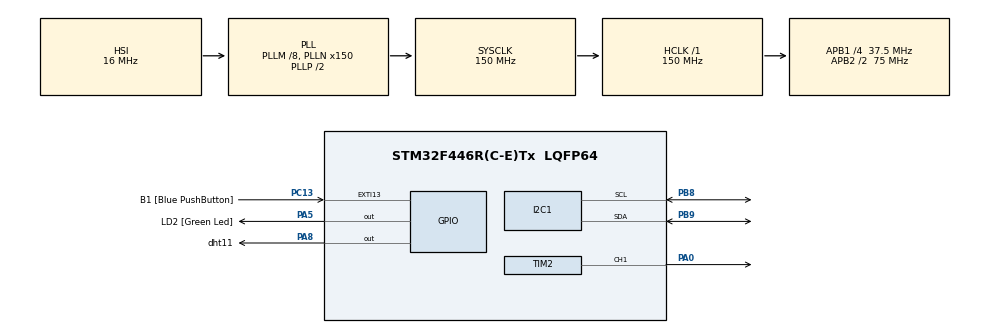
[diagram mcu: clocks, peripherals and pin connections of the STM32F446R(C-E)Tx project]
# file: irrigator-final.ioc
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I2C1.I2C_Mode=I2C_Fast
Mcu.Family=STM32F4
Mcu.Name=STM32F446R(C-E)Tx
Mcu.Package=LQFP64
NVIC.PriorityGroup=NVIC_PRIORITYGROUP_0
PA0-WKUP.Signal=S_TIM2_CH1_ETR
PA5.GPIO_Label=LD2 [Green Led]
PA5.Signal=GPIO_Output
PA8.GPIO_Label=dht11
PA8.GPIO_Speed=GPIO_SPEED_FREQ_VERY_HIGH
PA8.PinState=GPIO_PIN_SET
PA8.Signal=GPIO_Output
PB8.Mode=I2C
PB8.Signal=I2C1_SCL
PB9.Mode=I2C
PB9.Signal=I2C1_SDA
PC13.GPIO_Label=B1 [Blue PushButton]
PC13.GPIO_ModeDefaultEXTI=GPIO_MODE_IT_FALLING
PC13.Signal=GPXTI13
PC14-OSC32_IN.Mode=LSE-External-Oscillator
PC14-OSC32_IN.Signal=RCC_OSC32_IN
PC15-OSC32_OUT.Mode=LSE-External-Oscillator
PC15-OSC32_OUT.Signal=RCC_OSC32_OUT
PH0-OSC_IN.Mode=HSE-External-Oscillator
PH0-OSC_IN.Signal=RCC_OSC_IN
PH1-OSC_OUT.Mode=HSE-External-Oscillator
PH1-OSC_OUT.Signal=RCC_OSC_OUT
ProjectManager.HeapSize=0x200
ProjectManager.StackSize=0x400
ProjectManager.TargetToolchain=STM32CubeIDE
RCC.AHBFreq_Value=150000000
RCC.APB1CLKDivider=RCC_HCLK_DIV4
RCC.APB1Freq_Value=37500000
RCC.APB1TimFreq_Value=75000000
RCC.APB2CLKDivider=RCC_HCLK_DIV2
RCC.APB2Freq_Value=75000000
RCC.APB2TimFreq_Value=150000000
RCC.CortexFreq_Value=150000000
RCC.FLatency-AdvancedSettings=FLASH_LATENCY_4
RCC.HCLKFreq_Value=150000000
RCC.HSE_VALUE=8000000
RCC.HSI_VALUE=16000000
RCC.PLLM=8
RCC.PLLN=150
RCC.SYSCLKFreq_VALUE=150000000
RCC.SYSCLKSource=RCC_SYSCLKSOURCE_PLLCLK
RCC.USBFreq_Value=150000000
RCC.VCOOutputFreq_Value=300000000
SH.S_TIM2_CH1_ETR.0=TIM2_CH1,PWM Generation1 CH1
TIM2.Channel-PWM\ Generation1\ CH1=TIM_CHANNEL_1
TIM2.Period=1000-1
TIM2.Prescaler=1680-1
VP_TIM2_VS_ClockSourceINT.Mode=Internal
board=NUCLEO-F446RE

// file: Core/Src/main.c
/* USER CODE BEGIN Header */
/**
  ******************************************************************************
  * @file           : main.c
  * @brief          : Main program body
  ******************************************************************************
  * @attention
  *
  * Copyright (c) 2024 STMicroelectronics.
  * All rights reserved.
  *
  * This software is licensed under terms that can be found in the LICENSE file
  * in the root directory of this software component.
  * If no LICENSE file comes with this software, it is provided AS-IS.
  *
  ******************************************************************************
  */
/* USER CODE END Header */
#include "main.h"

/* USER CODE BEGIN Includes */
#include <stdio.h>
#include "ssd1306.h"
#include "timer_display.h"
#include "servo_control.h"
#include "pir_control.h"

/* USER CODE END Includes */

I2C_HandleTypeDef hi2c1;

TIM_HandleTypeDef htim2;

/* USER CODE BEGIN PV */

/* USER CODE BEGIN PV */
/* USER CODE END PV */

void SystemClock_Config(void);
static void MX_GPIO_Init(void);
static void MX_I2C1_Init(void);
static void MX_TIM2_Init(void);

int main(void)
{

  /* MCU Configuration--------------------------------------------------------*/

  /* Reset of all peripherals, Initializes the Flash interface and the Systick. */
  HAL_Init();

  /* Configure the system clock */
  SystemClock_Config();

  /* Initialize all configured peripherals */
  MX_GPIO_Init();
  MX_I2C1_Init();
  MX_TIM2_Init();
  /* USER CODE BEGIN 2 */
  /* USER CODE BEGIN 2 */

  Timer_Display_Init();
	Servo_Init();

  /* USER CODE END 2 */

  /* Infinite loop */
  /* USER CODE BEGIN WHILE */
  while (1)
  {
  	Timer_Display_Update();
		PIR_Process();
    /* USER CODE END WHILE */

  }
}

void SystemClock_Config(void)
{
  RCC_OscInitTypeDef RCC_OscInitStruct = {0};
  RCC_ClkInitTypeDef RCC_ClkInitStruct = {0};

  /** Configure the main internal regulator output voltage
  */
  __HAL_RCC_PWR_CLK_ENABLE();
  __HAL_PWR_VOLTAGESCALING_CONFIG(PWR_REGULATOR_VOLTAGE_SCALE1);

  /** Initializes the RCC Oscillators according to the specified parameters
  * in the RCC_OscInitTypeDef structure.
  */
  RCC_OscInitStruct.OscillatorType = RCC_OSCILLATORTYPE_HSI;
  RCC_OscInitStruct.HSIState = RCC_HSI_ON;
  RCC_OscInitStruct.HSICalibrationValue = RCC_HSICALIBRATION_DEFAULT;
  RCC_OscInitStruct.PLL.PLLState = RCC_PLL_ON;
  RCC_OscInitStruct.PLL.PLLSource = RCC_PLLSOURCE_HSI;
  RCC_OscInitStruct.PLL.PLLM = 8;
  RCC_OscInitStruct.PLL.PLLN = 150;
  RCC_OscInitStruct.PLL.PLLP = RCC_PLLP_DIV2;
  RCC_OscInitStruct.PLL.PLLQ = 2;
  RCC_OscInitStruct.PLL.PLLR = 2;
  if (HAL_RCC_OscConfig(&RCC_OscInitStruct) != HAL_OK)
  {
    Error_Handler();
  }

  /** Initializes the CPU, AHB and APB buses clocks
  */
  RCC_ClkInitStruct.ClockType = RCC_CLOCKTYPE_HCLK|RCC_CLOCKTYPE_SYSCLK
                              |RCC_CLOCKTYPE_PCLK1|RCC_CLOCKTYPE_PCLK2;
  RCC_ClkInitStruct.SYSCLKSource = RCC_SYSCLKSOURCE_PLLCLK;
  RCC_ClkInitStruct.AHBCLKDivider = RCC_SYSCLK_DIV1;
  RCC_ClkInitStruct.APB1CLKDivider = RCC_HCLK_DIV4;
  RCC_ClkInitStruct.APB2CLKDivider = RCC_HCLK_DIV2;

  if (HAL_RCC_ClockConfig(&RCC_ClkInitStruct, FLASH_LATENCY_4) != HAL_OK)
  {
    Error_Handler();
  }
}

static void MX_I2C1_Init(void)
{

  hi2c1.Instance = I2C1;
  hi2c1.Init.ClockSpeed = 400000;
  hi2c1.Init.DutyCycle = I2C_DUTYCYCLE_2;
  hi2c1.Init.OwnAddress1 = 0;
  hi2c1.Init.AddressingMode = I2C_ADDRESSINGMODE_7BIT;
  hi2c1.Init.DualAddressMode = I2C_DUALADDRESS_DISABLE;
  hi2c1.Init.OwnAddress2 = 0;
  hi2c1.Init.GeneralCallMode = I2C_GENERALCALL_DISABLE;
  hi2c1.Init.NoStretchMode = I2C_NOSTRETCH_DISABLE;
  if (HAL_I2C_Init(&hi2c1) != HAL_OK)
  {
    Error_Handler();
  }

}

static void MX_TIM2_Init(void)
{

  TIM_ClockConfigTypeDef sClockSourceConfig = {0};
  TIM_MasterConfigTypeDef sMasterConfig = {0};
  TIM_OC_InitTypeDef sConfigOC = {0};

  htim2.Instance = TIM2;
  htim2.Init.Prescaler = 1680-1;
  htim2.Init.CounterMode = TIM_COUNTERMODE_UP;
  htim2.Init.Period = 1000-1;
  htim2.Init.ClockDivision = TIM_CLOCKDIVISION_DIV1;
  htim2.Init.AutoReloadPreload = TIM_AUTORELOAD_PRELOAD_DISABLE;
  if (HAL_TIM_Base_Init(&htim2) != HAL_OK)
  {
    Error_Handler();
  }
  sClockSourceConfig.ClockSource = TIM_CLOCKSOURCE_INTERNAL;
  if (HAL_TIM_ConfigClockSource(&htim2, &sClockSourceConfig) != HAL_OK)
  {
    Error_Handler();
  }
  if (HAL_TIM_PWM_Init(&htim2) != HAL_OK)
  {
    Error_Handler();
  }
  sMasterConfig.MasterOutputTrigger = TIM_TRGO_RESET;
  sMasterConfig.MasterSlaveMode = TIM_MASTERSLAVEMODE_DISABLE;
  if (HAL_TIMEx_MasterConfigSynchronization(&htim2, &sMasterConfig) != HAL_OK)
  {
    Error_Handler();
  }
  sConfigOC.OCMode = TIM_OCMODE_PWM1;
  sConfigOC.Pulse = 0;
  sConfigOC.OCPolarity = TIM_OCPOLARITY_HIGH;
  sConfigOC.OCFastMode = TIM_OCFAST_DISABLE;
  if (HAL_TIM_PWM_ConfigChannel(&htim2, &sConfigOC, TIM_CHANNEL_1) != HAL_OK)
  {
    Error_Handler();
  }
  HAL_TIM_MspPostInit(&htim2);

}

static void MX_GPIO_Init(void)
{
  GPIO_InitTypeDef GPIO_InitStruct = {0};

  /* GPIO Ports Clock Enable */
  __HAL_RCC_GPIOC_CLK_ENABLE();
  __HAL_RCC_GPIOH_CLK_ENABLE();
  __HAL_RCC_GPIOA_CLK_ENABLE();
  __HAL_RCC_GPIOB_CLK_ENABLE();

  /*Configure GPIO pin Output Level */
  HAL_GPIO_WritePin(LD2_GPIO_Port, LD2_Pin, GPIO_PIN_RESET);

  /*Configure GPIO pin Output Level */
  HAL_GPIO_WritePin(dht11_GPIO_Port, dht11_Pin, GPIO_PIN_SET);

  /*Configure GPIO pin : B1_Pin */
  GPIO_InitStruct.Pin = B1_Pin;
  GPIO_InitStruct.Mode = GPIO_MODE_IT_FALLING;
  GPIO_InitStruct.Pull = GPIO_NOPULL;
  HAL_GPIO_Init(B1_GPIO_Port, &GPIO_InitStruct);

  /*Configure GPIO pin : LD2_Pin */
  GPIO_InitStruct.Pin = LD2_Pin;
  GPIO_InitStruct.Mode = GPIO_MODE_OUTPUT_PP;
  GPIO_InitStruct.Pull = GPIO_NOPULL;
  GPIO_InitStruct.Speed = GPIO_SPEED_FREQ_LOW;
  HAL_GPIO_Init(LD2_GPIO_Port, &GPIO_InitStruct);

  /*Configure GPIO pin : dht11_Pin */
  GPIO_InitStruct.Pin = dht11_Pin;
  GPIO_InitStruct.Mode = GPIO_MODE_OUTPUT_PP;
  GPIO_InitStruct.Pull = GPIO_NOPULL;
  GPIO_InitStruct.Speed = GPIO_SPEED_FREQ_VERY_HIGH;
  HAL_GPIO_Init(dht11_GPIO_Port, &GPIO_InitStruct);

}

void Error_Handler(void)
{
  __disable_irq();
  while (1)
  {
  }
}
